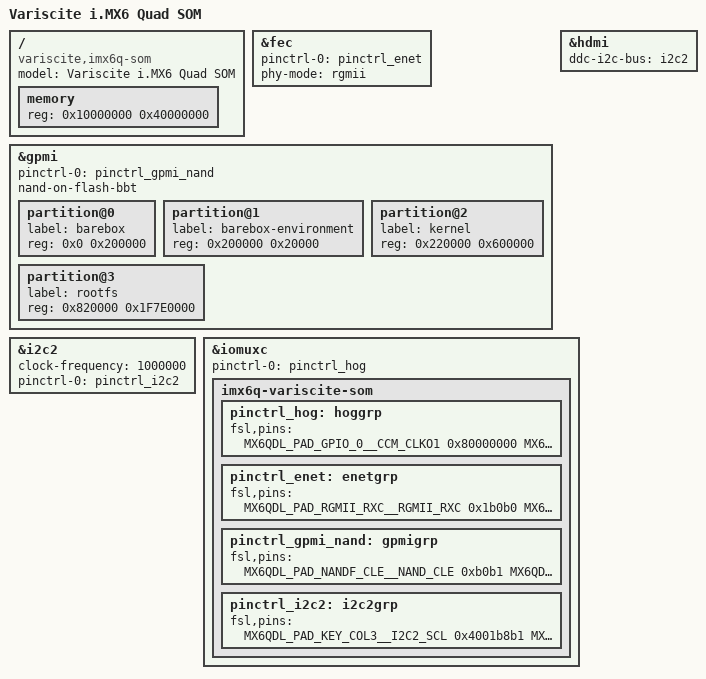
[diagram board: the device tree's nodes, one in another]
/*
 * Copyright 2013 Michael Burkey
 * Based on code written by Christian Hemp, Phytec Messtechnik GmbH
 *
 * The code contained herein is licensed under the GNU General Public
 * License. You may obtain a copy of the GNU General Public License
 * Version 2 or later at the following locations:
 *
 * http://www.opensource.org/licenses/gpl-license.html
 * http://www.gnu.org/copyleft/gpl.html
 */

#include "imx6q.dtsi"

/ {
	model = "Variscite i.MX6 Quad SOM";
	compatible = "variscite,imx6q-som", "fsl,imx6q";

	memory {
		reg = <0x10000000 0x40000000>;
	};
};

&fec {
	pinctrl-names = "default";
	pinctrl-0 = <&pinctrl_enet>;
	phy-mode = "rgmii";
	status = "okay";
};

&gpmi {
	pinctrl-names = "default";
	pinctrl-0 = <&pinctrl_gpmi_nand>;
	nand-on-flash-bbt;
	status = "okay";
	#address-cells = <1>;
	#size-cells = <1>;

	partition@0 {
		label = "barebox";
		reg = <0x0 0x200000>;
	};

	partition@1 {
		label = "barebox-environment";
		reg = <0x200000 0x20000>;
	};

	partition@2 {
		label = "kernel";
		reg = <0x220000 0x600000>;
	};

	partition@3 {
		label = "rootfs";
		reg = <0x820000 0x1F7E0000>;
	};
};

&hdmi {
	status = "okay";
	ddc-i2c-bus = <&i2c2>;
};

&i2c2 {
	status = "okay";
	clock-frequency = <1000000>;
	pinctrl-names = "default";
	pinctrl-0 = <&pinctrl_i2c2>;
};

&iomuxc {
	pinctrl-names = "default";
	pinctrl-0 = <&pinctrl_hog>;

	imx6q-variscite-som {
		pinctrl_hog: hoggrp {
			fsl,pins = <
				MX6QDL_PAD_GPIO_0__CCM_CLKO1	0x80000000
				MX6QDL_PAD_GPIO_3__CCM_CLKO2	0x80000000
			>;
		};

		pinctrl_enet: enetgrp {
			fsl,pins = <
				MX6QDL_PAD_RGMII_RXC__RGMII_RXC		0x1b0b0
				MX6QDL_PAD_RGMII_RD0__RGMII_RD0		0x1b0b0
				MX6QDL_PAD_RGMII_RD1__RGMII_RD1		0x1b0b0
				MX6QDL_PAD_RGMII_RD2__RGMII_RD2		0x1b0b0
				MX6QDL_PAD_RGMII_RD3__RGMII_RD3		0x1b0b0
				MX6QDL_PAD_RGMII_RX_CTL__RGMII_RX_CTL	0x1b0b0
				MX6QDL_PAD_RGMII_TXC__RGMII_TXC		0x1b0b0
				MX6QDL_PAD_RGMII_TD0__RGMII_TD0		0x1b0b0
				MX6QDL_PAD_RGMII_TD1__RGMII_TD1		0x1b0b0
				MX6QDL_PAD_RGMII_TD2__RGMII_TD2		0x1b0b0
				MX6QDL_PAD_RGMII_TD3__RGMII_TD3		0x1b0b0
				MX6QDL_PAD_RGMII_TX_CTL__RGMII_TX_CTL	0x1b0b0
				MX6QDL_PAD_ENET_REF_CLK__ENET_TX_CLK	0x1b0b0
				MX6QDL_PAD_ENET_MDIO__ENET_MDIO		0x1b0b0
				MX6QDL_PAD_ENET_MDC__ENET_MDC		0x1b0b0
				MX6QDL_PAD_ENET_CRS_DV__GPIO1_IO25	0x80000000 /* KSZ9031 PHY Reset */
			  >;
		};

		pinctrl_gpmi_nand: gpmigrp {
			fsl,pins = <
				MX6QDL_PAD_NANDF_CLE__NAND_CLE		0xb0b1
				MX6QDL_PAD_NANDF_ALE__NAND_ALE		0xb0b1
				MX6QDL_PAD_NANDF_WP_B__NAND_WP_B	0xb0b1
				MX6QDL_PAD_NANDF_RB0__NAND_READY_B	0xb000
				MX6QDL_PAD_NANDF_CS0__NAND_CE0_B	0xb0b1
				MX6QDL_PAD_NANDF_CS1__NAND_CE1_B	0xb0b1
				MX6QDL_PAD_SD4_CMD__NAND_RE_B		0xb0b1
				MX6QDL_PAD_SD4_CLK__NAND_WE_B		0xb0b1
				MX6QDL_PAD_NANDF_D0__NAND_DATA00	0xb0b1
				MX6QDL_PAD_NANDF_D1__NAND_DATA01	0xb0b1
				MX6QDL_PAD_NANDF_D2__NAND_DATA02	0xb0b1
				MX6QDL_PAD_NANDF_D3__NAND_DATA03	0xb0b1
				MX6QDL_PAD_NANDF_D4__NAND_DATA04	0xb0b1
				MX6QDL_PAD_NANDF_D5__NAND_DATA05	0xb0b1
				MX6QDL_PAD_NANDF_D6__NAND_DATA06	0xb0b1
				MX6QDL_PAD_NANDF_D7__NAND_DATA07	0xb0b1
				MX6QDL_PAD_SD4_DAT0__NAND_DQS		0x00b1
			>;
		};

		pinctrl_i2c2: i2c2grp {
			fsl,pins = <
				MX6QDL_PAD_KEY_COL3__I2C2_SCL		0x4001b8b1
				MX6QDL_PAD_KEY_ROW3__I2C2_SDA		0x4001b8b1
			>;
		};
	};
};
